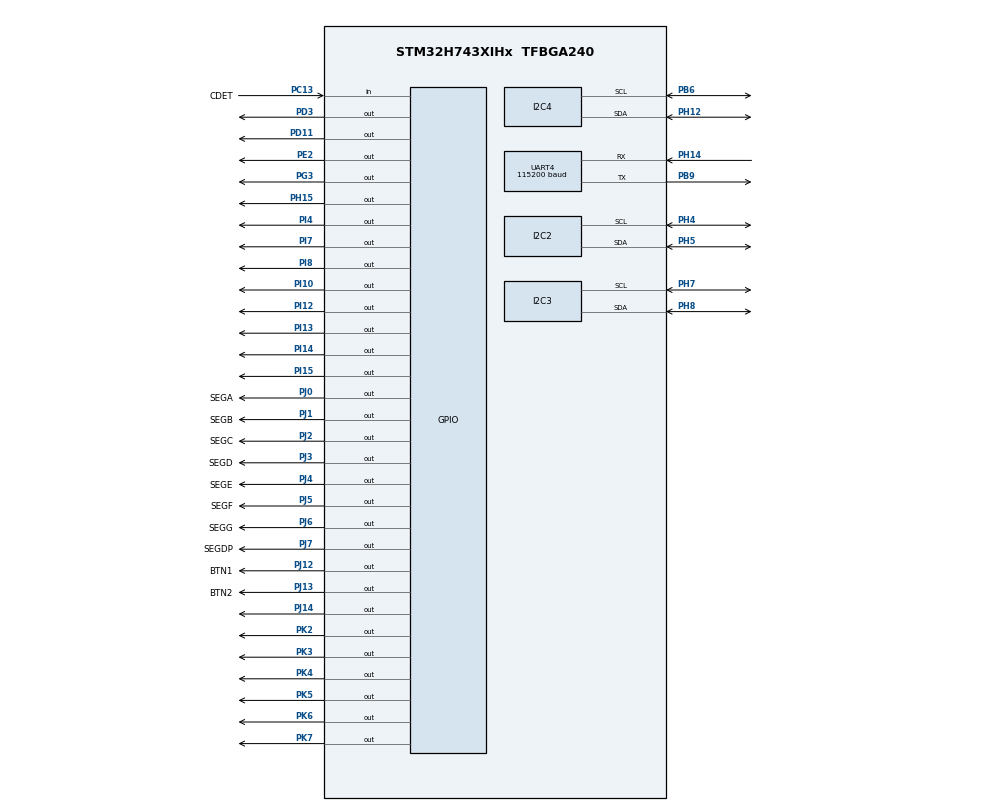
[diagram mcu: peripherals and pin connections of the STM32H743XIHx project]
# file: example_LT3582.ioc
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Mcu.Family=STM32H7
PK7.Signal=GPIO_Output
PK3.Signal=GPIO_Output
PK5.Signal=GPIO_Output
RCC.CortexFreq_Value=480000000
PH12.Signal=I2C4_SDA
PH14.Signal=UART4_RX
RCC.HPRE=RCC_HCLK_DIV2
PH0-OSC_IN\ (PH0).Signal=RCC_OSC_IN
PC15-OSC32_OUT\ (OSC32_OUT).Mode=LSE-External-Oscillator
PA1_C.Signal=ADCx_INP1
RCC.PLLFRACN=0
I2C2.Timing=0x307075B1
PJ6.GPIO_Label=SEGG
RCC.PLL2FRACN=3072
PA15\ (JTDI).Signal=DEBUG_JTDI
PC13.GPIO_Label=CDET
PJ5.GPIO_Label=SEGF
RCC.SYSCLKSource=RCC_SYSCLKSOURCE_PLLCLK
ProjectManager.StackSize=0x400
PJ6.Signal=GPIO_Output
PA14\ (JTCK/SWCLK).Signal=DEBUG_JTCK-SWCLK
PA15\ (JTDI).Mode=JTAG_5_pins
PJ13.GPIO_Label=BTN2
PH5.Signal=I2C2_SDA
PJ2.Signal=GPIO_Output
I2C4.Timing=0x307075B1
UART4.BaudRate=115200
RCC.HCLKFreq_Value=240000000
PB6.Signal=I2C4_SCL
PB6.Mode=I2C
PI13.Signal=GPIO_Output
SH.ADCx_INN1.0=ADC2_INN1
SH.ADCx_INN1.1=ADC1_INN1
PH1-OSC_OUT\ (PH1).Mode=HSE-External-Oscillator
RCC.HSE_VALUE=16000000
RCC.DIVM2=1
RCC.DIVM1=1
PI8.Signal=GPIO_Output
PJ7.GPIO_Label=SEGDP
PC13.GPIO_PuPd=GPIO_PULLUP
PJ12.GPIO_Label=BTN1
PE2.Signal=GPIO_Output
PA14\ (JTCK/SWCLK).Mode=JTAG_5_pins
PH7.Mode=I2C
RCC.APB3Freq_Value=120000000
PJ14.Signal=GPIO_Output
PB9.Signal=UART4_TX
Mcu.Package=TFBGA240
PH12.Mode=I2C
RCC.D1PPRE=RCC_APB3_DIV2
PJ12.Signal=GPIO_Output
PJ4.Signal=GPIO_Output
PJ1.Signal=GPIO_Output
PC14-OSC32_IN\ (OSC32_IN).Mode=LSE-External-Oscillator
PH7.Signal=I2C3_SCL
I2C3.Timing=0x307075B1
PJ3.GPIO_Label=SEGD
RCC.APB4Freq_Value=120000000
RCC.FDCANCLockSelection=RCC_FDCANCLKSOURCE_PLL2
PH8.Mode=I2C
PH0-OSC_IN\ (PH0).Mode=HSE-External-Oscillator
PJ1.GPIO_Label=SEGB
RCC.PLLSourceVirtual=RCC_PLLSOURCE_HSE
PK6.Signal=GPIO_Output
PK4.Signal=GPIO_Output
PH15.Signal=GPIO_Output
PK2.Signal=GPIO_Output
CORTEX_M7.CPU_ICache=Disabled
PA13\ (JTMS/SWDIO).Mode=JTAG_5_pins
PA0_C.Signal=ADCx_INN1
PG3.Signal=GPIO_Output
PC13.Signal=GPIO_Input
PI14.Signal=GPIO_Output
PD3.Signal=GPIO_Output
PD7.Signal=SPI1_MOSI
PI12.Signal=GPIO_Output
RCC.D2PPRE2=RCC_APB2_DIV2
RCC.D2PPRE1=RCC_APB1_DIV2
RCC.DIVP2=1
PI10.Signal=GPIO_Output
PH1-OSC_OUT\ (PH1).Signal=RCC_OSC_OUT
SH.ADCx_INP1.1=ADC1_INP1
SH.ADCx_INP1.0=ADC2_INP1
CORTEX_M7.MPU_Control=__NULL
PJ7.Signal=GPIO_Output
PJ3.Signal=GPIO_Output
PH4.Signal=I2C2_SCL
PB3\ (JTDO/TRACESWO).Signal=DEBUG_JTDO-SWO
ProjectManager.TargetToolchain=Makefile
PC15-OSC32_OUT\ (OSC32_OUT).Signal=RCC_OSC32_OUT
PH8.Signal=I2C3_SDA
PB9.Mode=Asynchronous
RCC.DIVN2=9
RCC.DIVN1=60
RCC.USBFreq_Value=48000000
RCC.USBCLockSelection=RCC_USBCLKSOURCE_HSI48
board=custom
PJ4.GPIO_Label=SEGE
PH14.Mode=Asynchronous
PI7.Signal=GPIO_Output
RCC.APB2Freq_Value=120000000
PI4.Signal=GPIO_Output
RCC.ADCFreq_Value=150000000
PB4\ (NJTRST).Mode=JTAG_5_pins
PJ0.Signal=GPIO_Output
Mcu.Name=STM32H743XIHx
PH4.Mode=I2C
RCC.SYSCLKFreq_VALUE=480000000
PC14-OSC32_IN\ (OSC32_IN).Signal=RCC_OSC32_IN
PD11.Signal=GPIO_Output
PJ5.Signal=GPIO_Output
PJ0.GPIO_Label=SEGA
ProjectManager.HeapSize=0x200
NVIC.PriorityGroup=NVIC_PRIORITYGROUP_4
PB3\ (JTDO/TRACESWO).Mode=JTAG_5_pins
PI15.Signal=GPIO_Output
RCC.D3PPRE=RCC_APB4_DIV2
PH5.Mode=I2C
CORTEX_M7.CPU_DCache=Disabled
RCC.APB1Freq_Value=120000000
PJ2.GPIO_Label=SEGC
PA13\ (JTMS/SWDIO).Signal=DEBUG_JTMS-SWDIO
PJ13.Signal=GPIO_Output
PB4\ (NJTRST).Signal=DEBUG_JTRST

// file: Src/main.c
/* USER CODE BEGIN Header */
/**
  ******************************************************************************
  * @file           : main.c
  * @brief          : Main program body
  ******************************************************************************
  * @attention
  *
  * <h2><center>&copy; Copyright (c) 2020 STMicroelectronics.
  * All rights reserved.</center></h2>
  *
  * This software component is licensed by ST under BSD 3-Clause license,
  * the "License"; You may not use this file except in compliance with the
  * License. You may obtain a copy of the License at:
  *                        opensource.org/licenses/BSD-3-Clause
  *
  ******************************************************************************
  */
/* USER CODE END Header */
#include "main.h"
#include "i2c.h"
#include "usart.h"
#include "gpio.h"

/* USER CODE BEGIN Includes */
#include "i2c_hal.h"
#include "lt3582.h"
/* USER CODE END Includes */

/* USER CODE BEGIN PV */
struct i2c_dev_s i2c_dev={&hi2c2, &i2c_mem_read, &i2c_mem_write, &i2c_master_transmit};  //TODO: change to init-fct-based approach
/* USER CODE END PV */

void SystemClock_Config(void);

int main(void)
{

  /* MCU Configuration--------------------------------------------------------*/

  /* Reset of all peripherals, Initializes the Flash interface and the Systick. */
  HAL_Init();

  /* Configure the system clock */
  SystemClock_Config();

  /* Initialize all configured peripherals */
  MX_GPIO_Init();
  MX_I2C2_Init();
  MX_I2C3_Init();
  MX_I2C4_Init();
  MX_UART4_Init();
  /* USER CODE BEGIN 2 */
  struct lt3582_dev_s lt3582_dev;
  uint8_t lt3582_adr = 0x62;  //address must be shifted to the left for HAL
  lt3582_init(&lt3582_dev, &i2c_dev, lt3582_adr);  //"constructor" for lt3582
  lt3582_dev.setVoltages(&lt3582_dev, 6.5, -7.2); //pos. voltage 6.5V, neg. voltage -7.2V
  /* USER CODE END 2 */

  /* Infinite loop */
  while (1)
  {

  }
}

void SystemClock_Config(void)
{
  RCC_OscInitTypeDef RCC_OscInitStruct = {0};
  RCC_ClkInitTypeDef RCC_ClkInitStruct = {0};
  RCC_PeriphCLKInitTypeDef PeriphClkInitStruct = {0};

  /** Supply configuration update enable
  */
  HAL_PWREx_ConfigSupply(PWR_LDO_SUPPLY);
  /** Configure the main internal regulator output voltage
  */
  __HAL_PWR_VOLTAGESCALING_CONFIG(PWR_REGULATOR_VOLTAGE_SCALE0);

  while(!__HAL_PWR_GET_FLAG(PWR_FLAG_VOSRDY)) {}
  /** Initializes the RCC Oscillators according to the specified parameters
  * in the RCC_OscInitTypeDef structure.
  */
  RCC_OscInitStruct.OscillatorType = RCC_OSCILLATORTYPE_HSE;
  RCC_OscInitStruct.HSEState = RCC_HSE_ON;
  RCC_OscInitStruct.PLL.PLLState = RCC_PLL_ON;
  RCC_OscInitStruct.PLL.PLLSource = RCC_PLLSOURCE_HSE;
  RCC_OscInitStruct.PLL.PLLM = 1;
  RCC_OscInitStruct.PLL.PLLN = 60;
  RCC_OscInitStruct.PLL.PLLP = 2;
  RCC_OscInitStruct.PLL.PLLQ = 2;
  RCC_OscInitStruct.PLL.PLLR = 2;
  RCC_OscInitStruct.PLL.PLLRGE = RCC_PLL1VCIRANGE_3;
  RCC_OscInitStruct.PLL.PLLVCOSEL = RCC_PLL1VCOWIDE;
  RCC_OscInitStruct.PLL.PLLFRACN = 0;
  if (HAL_RCC_OscConfig(&RCC_OscInitStruct) != HAL_OK)
  {
    Error_Handler();
  }
  /** Initializes the CPU, AHB and APB buses clocks
  */
  RCC_ClkInitStruct.ClockType = RCC_CLOCKTYPE_HCLK|RCC_CLOCKTYPE_SYSCLK
                              |RCC_CLOCKTYPE_PCLK1|RCC_CLOCKTYPE_PCLK2
                              |RCC_CLOCKTYPE_D3PCLK1|RCC_CLOCKTYPE_D1PCLK1;
  RCC_ClkInitStruct.SYSCLKSource = RCC_SYSCLKSOURCE_PLLCLK;
  RCC_ClkInitStruct.SYSCLKDivider = RCC_SYSCLK_DIV1;
  RCC_ClkInitStruct.AHBCLKDivider = RCC_HCLK_DIV2;
  RCC_ClkInitStruct.APB3CLKDivider = RCC_APB3_DIV2;
  RCC_ClkInitStruct.APB1CLKDivider = RCC_APB1_DIV2;
  RCC_ClkInitStruct.APB2CLKDivider = RCC_APB2_DIV2;
  RCC_ClkInitStruct.APB4CLKDivider = RCC_APB4_DIV2;

  if (HAL_RCC_ClockConfig(&RCC_ClkInitStruct, FLASH_LATENCY_4) != HAL_OK)
  {
    Error_Handler();
  }
  PeriphClkInitStruct.PeriphClockSelection = RCC_PERIPHCLK_UART4|RCC_PERIPHCLK_I2C2
                              |RCC_PERIPHCLK_I2C3|RCC_PERIPHCLK_I2C4;
  PeriphClkInitStruct.Usart234578ClockSelection = RCC_USART234578CLKSOURCE_D2PCLK1;
  PeriphClkInitStruct.I2c123ClockSelection = RCC_I2C123CLKSOURCE_D2PCLK1;
  PeriphClkInitStruct.I2c4ClockSelection = RCC_I2C4CLKSOURCE_D3PCLK1;
  if (HAL_RCCEx_PeriphCLKConfig(&PeriphClkInitStruct) != HAL_OK)
  {
    Error_Handler();
  }
}

void Error_Handler(void)
{
}

/************************ (C) COPYRIGHT STMicroelectronics *****END OF FILE****/
